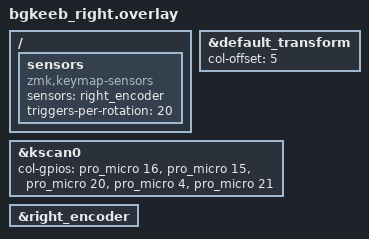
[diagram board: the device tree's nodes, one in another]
#include "bgkeeb.dtsi"

&default_transform {
    col-offset = <5>;
};

&kscan0 {
    col-gpios
        = <&pro_micro 16 GPIO_ACTIVE_HIGH>
        , <&pro_micro 15 GPIO_ACTIVE_HIGH>
        , <&pro_micro 20 GPIO_ACTIVE_HIGH>
        , <&pro_micro 4 GPIO_ACTIVE_HIGH>
        , <&pro_micro 21 GPIO_ACTIVE_HIGH>
        ;
};

&right_encoder {
    status = "okay";
};

/ {
    sensors: sensors {
        compatible = "zmk,keymap-sensors";
        sensors = <&right_encoder>;
        triggers-per-rotation = <20>;
    };
};
